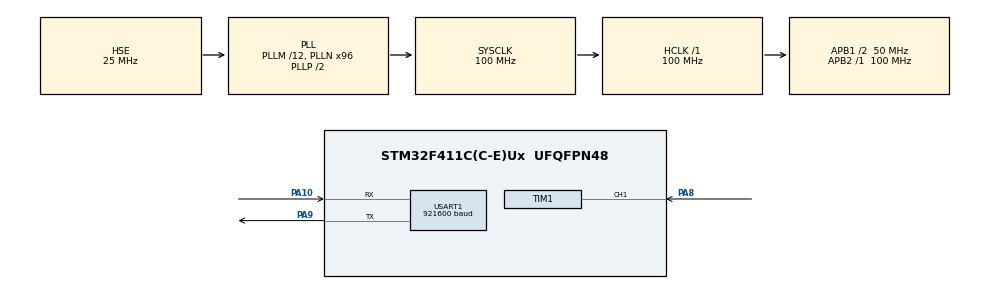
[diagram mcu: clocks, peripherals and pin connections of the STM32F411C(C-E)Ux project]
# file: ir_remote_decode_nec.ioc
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Mcu.Family=STM32F4
Mcu.Name=STM32F411C(C-E)Ux
Mcu.Package=UFQFPN48
NVIC.PriorityGroup=NVIC_PRIORITYGROUP_4
NVIC.TIM1_CC_IRQn=true\:0\:0\:false\:false\:true\:true\:true\:true
PA10.Mode=Asynchronous
PA10.Signal=USART1_RX
PA13.Mode=Serial_Wire
PA13.Signal=SYS_JTMS-SWDIO
PA14.Mode=Serial_Wire
PA14.Signal=SYS_JTCK-SWCLK
PA8.Signal=S_TIM1_CH1
PA9.Mode=Asynchronous
PA9.Signal=USART1_TX
PH0\ -\ OSC_IN.Mode=HSE-External-Oscillator
PH0\ -\ OSC_IN.Signal=RCC_OSC_IN
PH1\ -\ OSC_OUT.Mode=HSE-External-Oscillator
PH1\ -\ OSC_OUT.Signal=RCC_OSC_OUT
ProjectManager.HeapSize=0x200
ProjectManager.StackSize=0x400
ProjectManager.TargetToolchain=STM32CubeIDE
RCC.48MHZClocksFreq_Value=50000000
RCC.AHBFreq_Value=100000000
RCC.APB1CLKDivider=RCC_HCLK_DIV2
RCC.APB1Freq_Value=50000000
RCC.APB1TimFreq_Value=100000000
RCC.APB2Freq_Value=100000000
RCC.APB2TimFreq_Value=100000000
RCC.CortexFreq_Value=100000000
RCC.HCLKFreq_Value=100000000
RCC.HSE_VALUE=25000000
RCC.HSI_VALUE=16000000
RCC.LSE_VALUE=32768
RCC.PLLM=12
RCC.PLLN=96
RCC.PLLSourceVirtual=RCC_PLLSOURCE_HSE
RCC.SYSCLKFreq_VALUE=100000000
RCC.SYSCLKSource=RCC_SYSCLKSOURCE_PLLCLK
RCC.VCOOutputFreq_Value=200000000
SH.S_TIM1_CH1.0=TIM1_CH1,PWM_Input_1
TIM1.ICPolarity_1=TIM_INPUTCHANNELPOLARITY_RISING
TIM1.Prescaler=99
USART1.BaudRate=921600
USART1.VirtualMode=VM_ASYNC
VP_TIM1_VS_ClockSourceINT.Mode=Internal
board=custom

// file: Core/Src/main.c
/* USER CODE BEGIN Header */
/**
 ******************************************************************************
 * @file           : main.c
 * @brief          : Main program body
 ******************************************************************************
 * @attention
 *
 * Copyright (c) 2023 Lars Boegild Thomsen <lbthomsen@gmail.com>
 * All rights reserved.
 *
 * This software is licensed under terms that can be found in the LICENSE file
 * in the root directory of this software component.
 * If no LICENSE file comes with this software, it is provided AS-IS.
 *
 ******************************************************************************
 */
/* USER CODE END Header */
#include "main.h"

/* USER CODE BEGIN Includes */
#include <stdio.h>
/* USER CODE END Includes */

/* USER CODE BEGIN PTD */

typedef enum {
    IR_STATE_WAIT_MAKE,
    IR_STATE_WAIT_BREAK,
    IR_STATE_RECEIVE
} state_typedef;

/* USER CODE END PTD */

TIM_HandleTypeDef htim1;

UART_HandleTypeDef huart1;

void SystemClock_Config(void);
static void MX_GPIO_Init(void);
static void MX_TIM1_Init(void);
static void MX_USART1_UART_Init(void);
/* USER CODE BEGIN PFP */

void handle_data(uint16_t address, uint8_t data);

/* USER CODE END PFP */

/* USER CODE BEGIN 0 */

// Send printf to uart1
int _write(int fd, char *ptr, int len) {
    HAL_StatusTypeDef hstatus;

    if (fd == 1 || fd == 2) {
        hstatus = HAL_UART_Transmit(&huart1, (uint8_t*) ptr, len, HAL_MAX_DELAY);
        if (hstatus == HAL_OK)
            return len;
        else
            return -1;
    }
    return -1;
}

void HAL_TIM_IC_CaptureCallback(TIM_HandleTypeDef *htim) {

//    static uint8_t state = 0;
//    static uint8_t bit = 32;
//    static uint32_t received = 0;
    static state_typedef state = IR_STATE_WAIT_MAKE;
    static uint8_t bit;
    static uint8_t received[4];
    static uint32_t *received_buffer = (uint32_t *)&received[0];

    if (htim->Instance == TIM1) {

        uint32_t c2 = HAL_TIM_ReadCapturedValue(htim, TIM_CHANNEL_2);
        uint32_t c1 = HAL_TIM_ReadCapturedValue(htim, TIM_CHANNEL_1) - c2;

        DBG("Pulse %5lu %5lu", c1, c2);

        // Run the state machine
        if (state == IR_STATE_WAIT_MAKE) {
            if (c1 > 8000 && c1 < 10000) {
                DBG("Got make");
                state = IR_STATE_WAIT_BREAK;
            } else {
                DBG("Rubbish while waiting for make");
            }
        } else if (state == IR_STATE_WAIT_BREAK) {
            if (c2 > 4000 && c2 < 5000) {
                DBG("Got break");
                state = IR_STATE_RECEIVE;
                *received_buffer = 0x00000000;
                bit = 32;
            } else {
                DBG("Was expecting a break - got rubbish");
                state = IR_STATE_WAIT_MAKE;
            }
        } else if (state == IR_STATE_RECEIVE) {
            if (c2 > 1600 && c2 < 1800) {
                *received_buffer = *received_buffer | ((uint32_t) 1 << (bit - 1));
            } else if (c2 > 500 && c2 < 700) {
                // Accept this but does nothing
            } else {
                DBG("Rubbish data received");
                state = IR_STATE_WAIT_MAKE;
            }
            --bit;
        } else {
            DBG("IR Uknown state");
        }

        if (state == IR_STATE_RECEIVE && bit == 0) { // We're done - let's process
            DBG("Done receiving A0 = %02x A1 = %02x D0 = %02x D1 = %02x", received[0], received[1], received[2], received[3]);
        }

//        if (state == 0 && c1 > 3000 && c1 < 5000) { // Initial break
//            DBG("Receive start");
//
//            state = 1;
//            bit = 32;
//            received = 0;
//
//        } else if (state == 1 && c1 > 1600 && c1 < 1800) {
//            received = received + ((uint32_t) 1 << (bit - 1));
//            --bit;
//        } else if (state == 1 && c1 > 500 && c1 < 700) {
//            --bit;
//        } else {
//            DBG("Odd state = %d bit = %d received = %lu c1 = %lu", state, bit, received, c1);
//        }
//
//        if (bit == 0) {
//            DBG("Got 0x%08lx", received);
//
//            uint8_t address_lo = (received & 0xff000000) >> 24;
//            uint8_t address_hi = (received & 0x00ff0000) >> 16;
//            uint8_t data = (received & 0x0000ff00) >> 8;
//            uint8_t data_inv = (received & 0x000000ff);
//
//            uint16_t address = address_lo == ~address_hi ? address_lo : (address_hi << 8) + address_lo;
//            if (data == (uint8_t) ~data_inv) {
//                handle_data(address, data);
//            } else {
//                DBG("ERR");
//            }
//
//            state = 0;
//            bit = 32;
//            received = 0;
//        }

    }
}

void handle_data(uint16_t address, uint8_t data) {
    DBG("Addr = 0x%04x Data = 0x%02x", address, data);

}

/* USER CODE END 0 */

int main(void) {

    /* MCU Configuration--------------------------------------------------------*/

    /* Reset of all peripherals, Initializes the Flash interface and the Systick. */
    HAL_Init();

    /* Configure the system clock */
    SystemClock_Config();

    /* Initialize all configured peripherals */
    MX_GPIO_Init();
    MX_TIM1_Init();
    MX_USART1_UART_Init();
    /* USER CODE BEGIN 2 */

    DBG("\n\n\n\n--------\nStarting");

    HAL_TIM_IC_Start_IT(&htim1, TIM_CHANNEL_1); // Primary channel - rising edge
    HAL_TIM_IC_Start(&htim1, TIM_CHANNEL_2);    // Secondary channel - falling edge

    /* USER CODE END 2 */

    /* Infinite loop */
    while (1) {

    }
}

void SystemClock_Config(void) {
    RCC_OscInitTypeDef RCC_OscInitStruct = { 0 };
    RCC_ClkInitTypeDef RCC_ClkInitStruct = { 0 };

    /** Configure the main internal regulator output voltage
     */
    __HAL_RCC_PWR_CLK_ENABLE();
    __HAL_PWR_VOLTAGESCALING_CONFIG(PWR_REGULATOR_VOLTAGE_SCALE1);

    /** Initializes the RCC Oscillators according to the specified parameters
     * in the RCC_OscInitTypeDef structure.
     */
    RCC_OscInitStruct.OscillatorType = RCC_OSCILLATORTYPE_HSE;
    RCC_OscInitStruct.HSEState = RCC_HSE_ON;
    RCC_OscInitStruct.PLL.PLLState = RCC_PLL_ON;
    RCC_OscInitStruct.PLL.PLLSource = RCC_PLLSOURCE_HSE;
    RCC_OscInitStruct.PLL.PLLM = 12;
    RCC_OscInitStruct.PLL.PLLN = 96;
    RCC_OscInitStruct.PLL.PLLP = RCC_PLLP_DIV2;
    RCC_OscInitStruct.PLL.PLLQ = 4;
    if (HAL_RCC_OscConfig(&RCC_OscInitStruct) != HAL_OK) {
        Error_Handler();
    }

    /** Initializes the CPU, AHB and APB buses clocks
     */
    RCC_ClkInitStruct.ClockType = RCC_CLOCKTYPE_HCLK | RCC_CLOCKTYPE_SYSCLK | RCC_CLOCKTYPE_PCLK1 | RCC_CLOCKTYPE_PCLK2;
    RCC_ClkInitStruct.SYSCLKSource = RCC_SYSCLKSOURCE_PLLCLK;
    RCC_ClkInitStruct.AHBCLKDivider = RCC_SYSCLK_DIV1;
    RCC_ClkInitStruct.APB1CLKDivider = RCC_HCLK_DIV2;
    RCC_ClkInitStruct.APB2CLKDivider = RCC_HCLK_DIV1;

    if (HAL_RCC_ClockConfig(&RCC_ClkInitStruct, FLASH_LATENCY_3) != HAL_OK) {
        Error_Handler();
    }
}

static void MX_TIM1_Init(void) {

    TIM_ClockConfigTypeDef sClockSourceConfig = { 0 };
    TIM_SlaveConfigTypeDef sSlaveConfig = { 0 };
    TIM_IC_InitTypeDef sConfigIC = { 0 };
    TIM_MasterConfigTypeDef sMasterConfig = { 0 };

    htim1.Instance = TIM1;
    htim1.Init.Prescaler = 99;
    htim1.Init.CounterMode = TIM_COUNTERMODE_UP;
    htim1.Init.Period = 65535;
    htim1.Init.ClockDivision = TIM_CLOCKDIVISION_DIV1;
    htim1.Init.RepetitionCounter = 0;
    htim1.Init.AutoReloadPreload = TIM_AUTORELOAD_PRELOAD_DISABLE;
    if (HAL_TIM_Base_Init(&htim1) != HAL_OK) {
        Error_Handler();
    }
    sClockSourceConfig.ClockSource = TIM_CLOCKSOURCE_INTERNAL;
    if (HAL_TIM_ConfigClockSource(&htim1, &sClockSourceConfig) != HAL_OK) {
        Error_Handler();
    }
    if (HAL_TIM_IC_Init(&htim1) != HAL_OK) {
        Error_Handler();
    }
    sSlaveConfig.SlaveMode = TIM_SLAVEMODE_RESET;
    sSlaveConfig.InputTrigger = TIM_TS_TI1FP1;
    sSlaveConfig.TriggerPolarity = TIM_INPUTCHANNELPOLARITY_RISING;
    sSlaveConfig.TriggerPrescaler = TIM_ICPSC_DIV1;
    sSlaveConfig.TriggerFilter = 0;
    if (HAL_TIM_SlaveConfigSynchro(&htim1, &sSlaveConfig) != HAL_OK) {
        Error_Handler();
    }
    sConfigIC.ICPolarity = TIM_INPUTCHANNELPOLARITY_RISING;
    sConfigIC.ICSelection = TIM_ICSELECTION_DIRECTTI;
    sConfigIC.ICPrescaler = TIM_ICPSC_DIV1;
    sConfigIC.ICFilter = 0;
    if (HAL_TIM_IC_ConfigChannel(&htim1, &sConfigIC, TIM_CHANNEL_1) != HAL_OK) {
        Error_Handler();
    }
    sConfigIC.ICPolarity = TIM_INPUTCHANNELPOLARITY_FALLING;
    sConfigIC.ICSelection = TIM_ICSELECTION_INDIRECTTI;
    if (HAL_TIM_IC_ConfigChannel(&htim1, &sConfigIC, TIM_CHANNEL_2) != HAL_OK) {
        Error_Handler();
    }
    sMasterConfig.MasterOutputTrigger = TIM_TRGO_RESET;
    sMasterConfig.MasterSlaveMode = TIM_MASTERSLAVEMODE_DISABLE;
    if (HAL_TIMEx_MasterConfigSynchronization(&htim1, &sMasterConfig) != HAL_OK) {
        Error_Handler();
    }

}

static void MX_USART1_UART_Init(void) {

    huart1.Instance = USART1;
    huart1.Init.BaudRate = 921600;
    huart1.Init.WordLength = UART_WORDLENGTH_8B;
    huart1.Init.StopBits = UART_STOPBITS_1;
    huart1.Init.Parity = UART_PARITY_NONE;
    huart1.Init.Mode = UART_MODE_TX_RX;
    huart1.Init.HwFlowCtl = UART_HWCONTROL_NONE;
    huart1.Init.OverSampling = UART_OVERSAMPLING_16;
    if (HAL_UART_Init(&huart1) != HAL_OK) {
        Error_Handler();
    }

}

static void MX_GPIO_Init(void) {

    /* GPIO Ports Clock Enable */
    __HAL_RCC_GPIOH_CLK_ENABLE();
    __HAL_RCC_GPIOA_CLK_ENABLE();

}

void Error_Handler(void) {
    __disable_irq();
    while (1) {
    }
}
